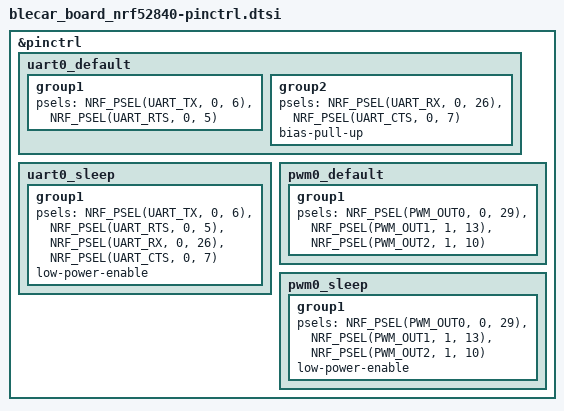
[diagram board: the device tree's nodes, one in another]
&pinctrl {
    uart0_default: uart0_default {
        group1 {
            psels = <NRF_PSEL(UART_TX, 0, 6)>,
                <NRF_PSEL(UART_RTS, 0, 5)>;
        };
        group2 {
            psels = <NRF_PSEL(UART_RX, 0, 26)>,
                <NRF_PSEL(UART_CTS, 0, 7)>;
                bias-pull-up;
        };
    };

    uart0_sleep: uart0_sleep {
        group1 {
            psels = <NRF_PSEL(UART_TX, 0, 6)>,
                <NRF_PSEL(UART_RTS, 0, 5)>,
                <NRF_PSEL(UART_RX, 0, 26)>,
                <NRF_PSEL(UART_CTS, 0, 7)>;
            low-power-enable;
        };
    };

    pwm0_default: pwm0_default {
		group1 {
			psels = <NRF_PSEL(PWM_OUT0, 0, 29)>,
		   <NRF_PSEL(PWM_OUT1, 1, 13)>,
		   <NRF_PSEL(PWM_OUT2, 1, 10)>;
		};
	};
    pwm0_sleep: pwm0_sleep {
		group1 {
			psels = <NRF_PSEL(PWM_OUT0, 0, 29)>,
		   <NRF_PSEL(PWM_OUT1, 1, 13)>,
		   <NRF_PSEL(PWM_OUT2, 1, 10)>;
           low-power-enable;
		};
	};
};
